# STM32MP21_CA35 register map
File version: 0.4
CPU: CM33 r0p1, little endian, MPU, FPU, vendor SysTick, 8 interrupt priority bits
Registers are 32-bit, read-write, reset 0x0 unless marked. A register's access mark holds for its fields unless they carry their own. Offsets are from the block's base; [hi:lo] are bit positions; {n}, {i} and the like mark numbered series; 'fields as' and 'values as' point back to an identical list.

## RISAF1 — RISAF register block
Base 0x420A0000
Same registers: RISAF1_S 0x520A0000
0x00 RISAF1_CR — RISAF configuration register
  [0] GLOCK — Global lock
    0=RISAF registers are writable; 1=All writes to RISAF registers are ignored, except RISAF_IACR, RISAF_REGx_zCFGR, RISAF_REGx_zSTARTR and RISAF_REGx_zENDR (z = A to B)
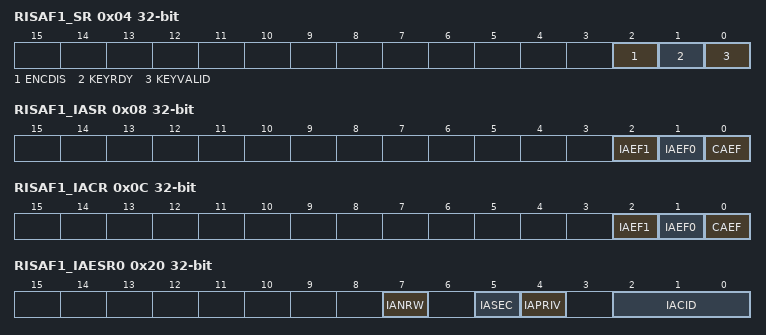
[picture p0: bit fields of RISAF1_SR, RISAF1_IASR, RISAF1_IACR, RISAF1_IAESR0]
0x04 RISAF1_SR ro — RISAF status register
  [2] ENCDIS — Encryption disabled
    0=When ENC[1:0] = 0x1 or 0x2 and BREN is set in RISAF_REGx_CFGR, all allowed write accesses in region x are encrypted, and all allowed read requests are decrypted; 1=When ENC[1:0] = 0x1 or 0x2 and BREN is set in RISAF_REGx_CFGR, all write accesses in region x are ignored, and all read requests return 0
  [1] KEYRDY — Key ready
    0=The most recently written key in RISAF_KEYRy is being expanded; 1=The most recently written key in RISAF_KEYRy is ready for use
  [0] KEYVALID
    0=A valid key has not been written in RISAF_KEYRy; 1=A valid key has been written in RISAF_KEYRy
0x08 RISAF1_IASR ro — RISAF illegal access status register
  [2] IAEF1 — Illegal access error flag 1
  [1] IAEF0 — Illegal access error flag 0
  [0] CAEF — Configuration access error flag
0x0C RISAF1_IACR wo — RISAF illegal access clear register
  fields as RISAF1_IASR
0x20 RISAF1_IAESR0 ro — RISAF illegal access error status register 0
  [7] IANRW — Illegal access read/write
    0=Illegal access was a data read or an instruction fetch; 1=Illegal access was a data write
  [5] IASEC — Illegal access security
    0=Illegal access was nonsecure; 1=Illegal access was secure
  [4] IAPRIV — Illegal access privileged
    0=Illegal access was unprivileged; 1=Illegal access was privileged
  [2:0] IACID — Illegal access compartment ID
0x24 RISAF1_IADDR0 ro — RISAF illegal address register 0
  [31:0] IADD — Illegal address
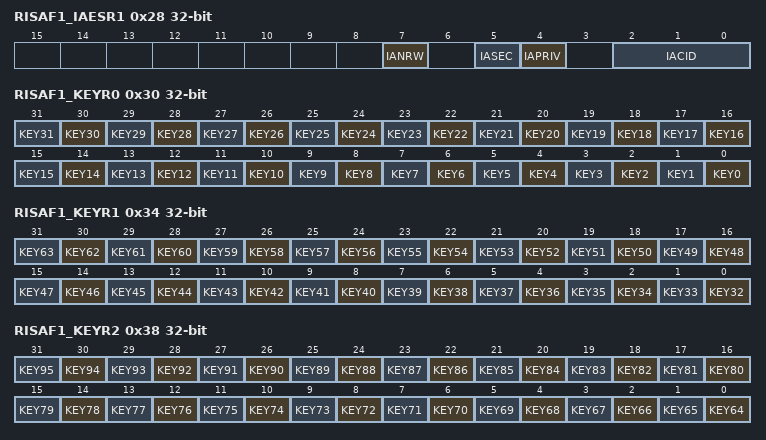
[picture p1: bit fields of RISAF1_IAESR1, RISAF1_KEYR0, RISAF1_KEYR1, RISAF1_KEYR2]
0x28 RISAF1_IAESR1 ro — RISAF illegal access error status register 1
  fields as RISAF1_IAESR0
0x2C RISAF1_IADDR1 ro — RISAF illegal address register 1
  [31:0] IADD — Illegal address
0x30 RISAF1_KEYR0 wo — RISAF encryption key 0
  [n] KEY{n} (n=0..31) — Cryptographic key
0x34 RISAF1_KEYR1 wo — RISAF encryption key 1
  [n-32] KEY{n} (n=32..63) — Cryptographic key
0x38 RISAF1_KEYR2 wo — RISAF encryption key 2
  [n-64] KEY{n} (n=64..95) — Cryptographic key
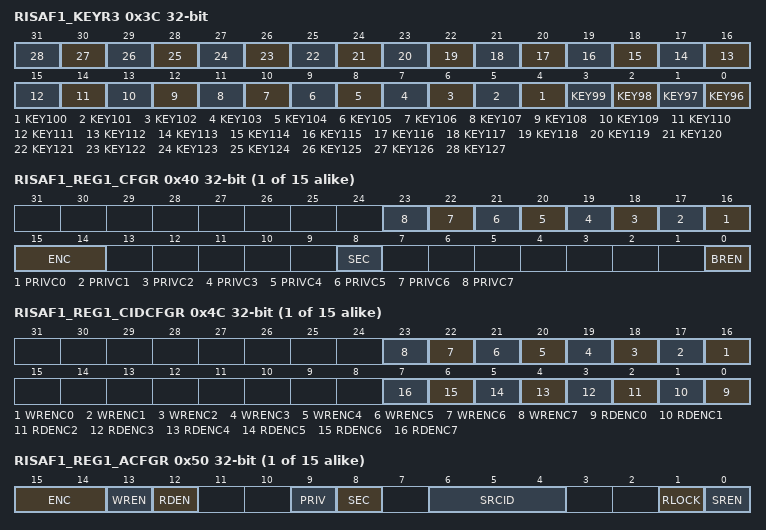
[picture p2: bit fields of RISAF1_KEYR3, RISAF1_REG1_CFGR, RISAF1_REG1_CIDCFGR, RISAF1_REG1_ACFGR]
0x3C RISAF1_KEYR3 wo — RISAF encryption key 3
  [n-96] KEY{n} (n=96..127) — Cryptographic key
{0x0+0x40*i} RISAF1_REG{i}_CFGR (i=1..15) — RISAF region {i} configuration register
  [n+16] PRIVC{n} (n=0..7) — Privileged access for compartment y
    0=Application running in compartment y can access to region x in privileged and unprivileged mode; 1=Application running in compartment y can access to region x in privileged mode only
  [15:14] ENC — Encrypted region
    0=No effect; 1=All allowed write accesses are encrypted, all allowed read requests are decrypted; 2=All allowed write accesses are encrypted, all allowed read requests are decrypted, when KEYRDY is set in RISAF_SR (to be used for secure regions only); 3=No effect
  [8] SEC — Secure region
    0=Only nonsecure requests can access region x; 1=Only secure requests can access region x, and optional subregions can be defined as secure or nonsecure
  [0] BREN — Base region enable
    0=Base region x is disabled; 1=Base region x is enabled
{0x4+0x40*i} RISAF1_REG{i}_STARTR (i=1..15) — RISAF region {i} start-address register
  [31:0] BADDSTART — Base region address start
{0x8+0x40*i} RISAF1_REG{i}_ENDR reset 0xFFF (i=1..15) — RISAF region {i} end-address register
  [31:0] BADDEND — Base region address end
{0xC+0x40*i} RISAF1_REG{i}_CIDCFGR (i=1..15) — RISAF region {i} CID configuration register
  [n+16] WRENC{n} (n=0..7) — Write enable for compartment y
    0=Application running in compartment y cannot write to region x (write ignored); 1=Application running in compartment y can write to region x
  [n] RDENC{n} (n=0..7) — Read enable for compartment y
    0=Application running in compartment y cannot read region x (read as 0); 1=Application running in compartment y can read region x
{0x10+0x40*i} RISAF1_REG{i}_ACFGR (i=1..15) — RISAF region {i} subregion A configuration register
  [15:14] ENC ro — Encrypted subregion
    0=No effect; 3=No effect
  [13] WREN — Write enable
    0=Any writes to subregion A of region x are ignored; 1=Subregion A of region x can be written to
  [12] RDEN — Read enable
    0=Any read to subregion A of region x returns 0; 1=Subregion A of region x can be read
  [9] PRIV — Privileged subregion
    0=Privileged and unprivileged accesses are granted in subregion A of region x; 1=Only privileged accesses are granted in subregion A of region x
  [8] SEC — Secure subregion
    0=Only nonsecure requests can access subregion A of region x; 1=Only secure requests can access subregion A of region x
  [6:4] SRCID — Subregion CID
  [1] RLOCK — Resource lock
    0=RISAF_REGx_ACFGR, RISAF_REGx_ASTARTR, and RISAF_REGx_AENDR are writable; 1=Writes to RISAF_REGx_ACFGR, RISAF_REGx_ASTARTR, and RISAF_REGx_AENDR are ignored
  [0] SREN — Subregion enable
    0=Subregion A is disabled; 1=Subregion A of region x is enabled
{0x14+0x40*i} RISAF1_REG{i}_ASTARTR (i=1..15) — RISAF region {i} subregion A start-address register
  [31:0] SADDSTART — Subregion address start
{0x18+0x40*i} RISAF1_REG{i}_AENDR reset 0xFFF (i=1..15) — RISAF region {i} subregion A end-address register
  [31:0] SADDEND — Subregion address end
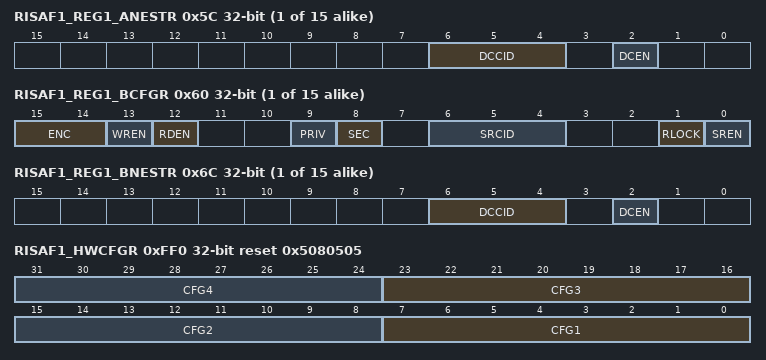
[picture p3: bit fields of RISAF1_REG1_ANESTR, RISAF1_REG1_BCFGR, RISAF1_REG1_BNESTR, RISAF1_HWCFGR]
{0x1C+0x40*i} RISAF1_REG{i}_ANESTR (i=1..15) — RISAF region {i} subregion A nested mode register
  [6:4] DCCID — Delegated configuration CID
  [2] DCEN — Delegated configuration enable
    0=RIF configuration for subregion A can be written only by the trusted domain; 1=RIF configuration for subregion A can be written only by compartment DCCID, defined in this register
{0x20+0x40*i} RISAF1_REG{i}_BCFGR (i=1..15) — RISAF region {i} subregion B configuration register
  [15:14] ENC ro — Encrypted subregion
    0=No effect; 3=No effect
  [13] WREN — Write enable
    0=Any writes to subregion B of region x are ignored; 1=Subregion B of region x can be written to
  [12] RDEN — Read enable
    0=Any read to subregion B of region x returns 0; 1=Subregion B of region x can be read
  [9] PRIV — Privileged subregion
    0=Privileged and unprivileged accesses are granted in subregion B of region x; 1=Only privileged accesses are granted in subregion B of region x
  [8] SEC — Secure subregion
    0=Only nonsecure requests can access subregion B of region x; 1=Only secure requests can access subregion B of region x
  [6:4] SRCID — Subregion CID
  [1] RLOCK — Resource lock
    0=RISAF_REGx_BCFGR, RISAF_REGx_BSTARTR, and RISAF_REGx_BENDR are writable; 1=Writes to RISAF_REGx_BCFGR, RISAF_REGx_BSTARTR, and RISAF_REGx_BENDR are ignored
  [0] SREN — Subregion enable
    0=Subregion B of region x is disabled; 1=Subregion B of region x is enabled
{0x24+0x40*i} RISAF1_REG{i}_BSTARTR (i=1..15) — RISAF region {i} subregion B start-address register
  [31:0] SADDSTART — Subregion address start
{0x28+0x40*i} RISAF1_REG{i}_BENDR reset 0xFFF (i=1..15) — RISAF region {i} subregion B end-address register
  [31:0] SADDEND — Subregion address end
{0x2C+0x40*i} RISAF1_REG{i}_BNESTR (i=1..15) — RISAF region {i} subregion B nested mode register
  [6:4] DCCID — Delegated configuration CID
  [2] DCEN — Delegated configuration enable
    0=RIF configuration for subregion B can be written only by the trusted domain; 1=RIF configuration for subregion B can be written only by compartment DCCID, defined in this register
0xFF0 RISAF1_HWCFGR ro reset 0x5080505 (reset mask 0x0) — RISAF hardware configuration register
  [8n-1:8n-8] CFG{n} (n=1..4) — Hardware generic {n}
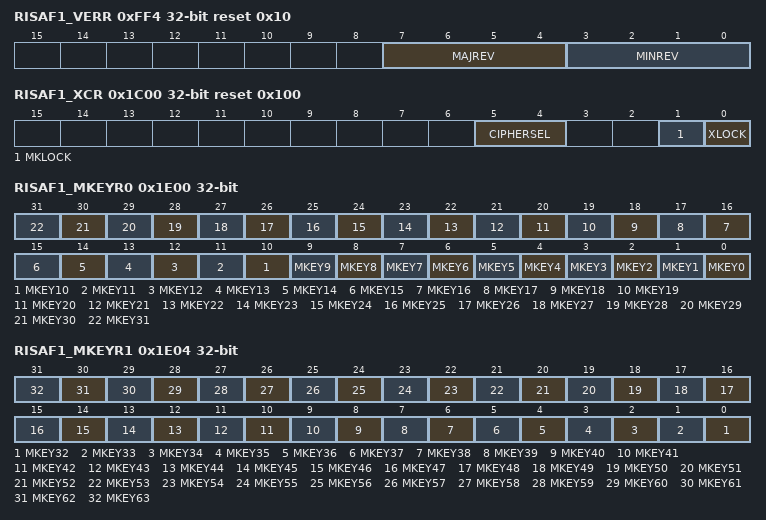
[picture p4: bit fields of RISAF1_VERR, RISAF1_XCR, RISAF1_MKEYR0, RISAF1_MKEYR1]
0xFF4 RISAF1_VERR ro reset 0x10 (reset mask 0x0) — RISAF version register
  [7:4] MAJREV — RISAF major revision
  [3:0] MINREV — RISAF minor revision
0xFF8 RISAF1_IPIDR ro reset 0x100166 (reset mask 0xFFFFFFF0) — RISAF identification register
  [31:0] ID — RISAF identification code
0xFFC RISAF1_SIDR ro reset 0xA3C5DD01 (reset mask 0xFFFFFFF0) — RISAF size identification register
  [31:0] SID — RISAF size identification code
0x1C00 RISAF1_XCR reset 0x100 — RISAF extended configuration register
  [5:4] CIPHERSEL — Cipher selection
    0=No cipher selected; 3=AES-256 cipher selected
  [1] MKLOCK — Master keys lock
    0=Writes to RISAF_MKEYRy registers are is allowed; 1=Writes to RISAF_MKEYRy registers are is ignored until next RISAF reset
  [0] XLOCK — Extended lock
    0=Extended registers are writable; 1=All writes to extended registers are ignored
0x1C04 RISAF1_XSR — RISAF extended status register
  [0] MKVALID — Master key valid
    0=A valid key has not been written in RISAF_MKEYRy registers, or a valid unlocked master key has been erased by hardware (if bit was set before); 1=A valid key has been written in RISAF_MKEYRy registers
0x1E00 RISAF1_MKEYR0 wo — RISAF master key 0
  [n] MKEY{n} (n=0..31) — Cryptographic key
0x1E04 RISAF1_MKEYR1 wo — RISAF master key 1
  [n-32] MKEY{n} (n=32..63) — Cryptographic key
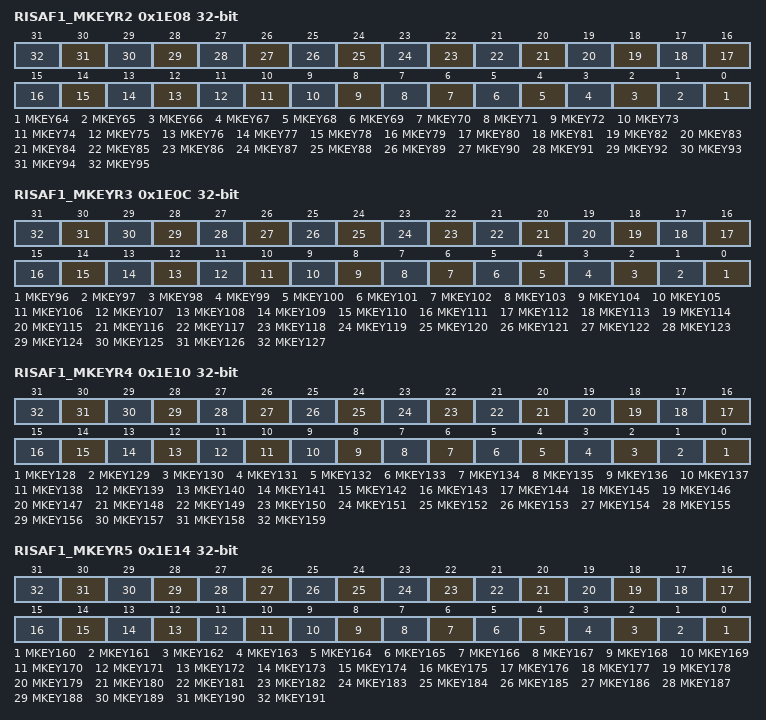
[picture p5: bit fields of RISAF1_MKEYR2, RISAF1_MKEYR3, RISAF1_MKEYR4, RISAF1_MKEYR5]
0x1E08 RISAF1_MKEYR2 wo — RISAF master key 2
  [n-64] MKEY{n} (n=64..95) — Cryptographic key
0x1E0C RISAF1_MKEYR3 wo — RISAF master key 3
  [n-96] MKEY{n} (n=96..127) — Cryptographic key
0x1E10 RISAF1_MKEYR4 wo — RISAF master key 4
  [n-128] MKEY{n} (n=128..159) — Cryptographic key
0x1E14 RISAF1_MKEYR5 wo — RISAF master key 5
  [n-160] MKEY{n} (n=160..191) — Cryptographic key
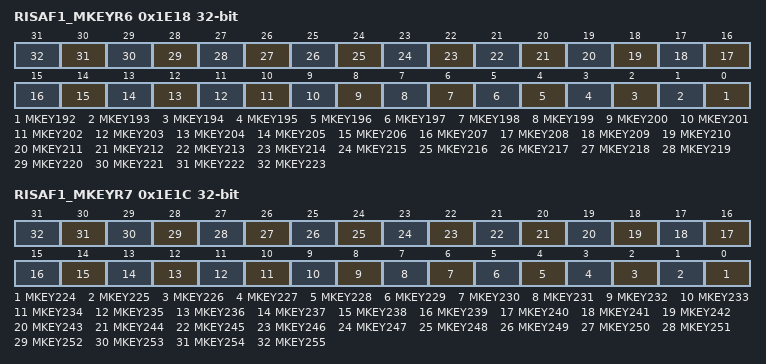
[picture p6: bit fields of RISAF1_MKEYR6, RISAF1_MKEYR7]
0x1E18 RISAF1_MKEYR6 wo — RISAF master key 6
  [n-192] MKEY{n} (n=192..223) — Cryptographic key
0x1E1C RISAF1_MKEYR7 wo — RISAF master key 7
  [n-224] MKEY{n} (n=224..255) — Cryptographic key

## RISAF2 — RISAF register block
Base 0x420B0000
Same registers: RISAF2_S 0x520B0000
Registers as RISAF1 (with RISAF1 read as RISAF2); these are added or differ:
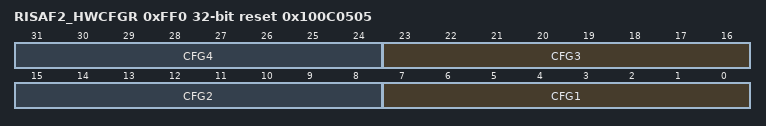
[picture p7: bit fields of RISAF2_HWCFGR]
0xFF0 RISAF2_HWCFGR ro reset 0x100C0505 (reset mask 0x0) — RISAF hardware configuration register
  [8n-1:8n-8] CFG{n} (n=1..4) — Hardware generic {n}

## RISAF4 — RISAF register block
Base 0x420D0000
Same registers: RISAF4_S 0x520D0000
Registers as RISAF1 (with RISAF1 read as RISAF4), without RISAF1_IPIDR, RISAF1_SIDR; these are added or differ:
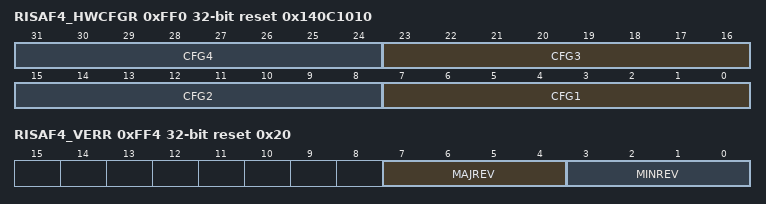
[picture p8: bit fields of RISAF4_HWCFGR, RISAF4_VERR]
0xFF0 RISAF4_HWCFGR ro reset 0x140C1010 (reset mask 0x0) — RISAF hardware configuration register
  [8n-1:8n-8] CFG{n} (n=1..4) — Hardware generic {n}
0xFF4 RISAF4_VERR ro reset 0x20 (reset mask 0x0) — RISAF version register
  [7:4] MAJREV — RISAF major revision
  [3:0] MINREV — RISAF minor revision
